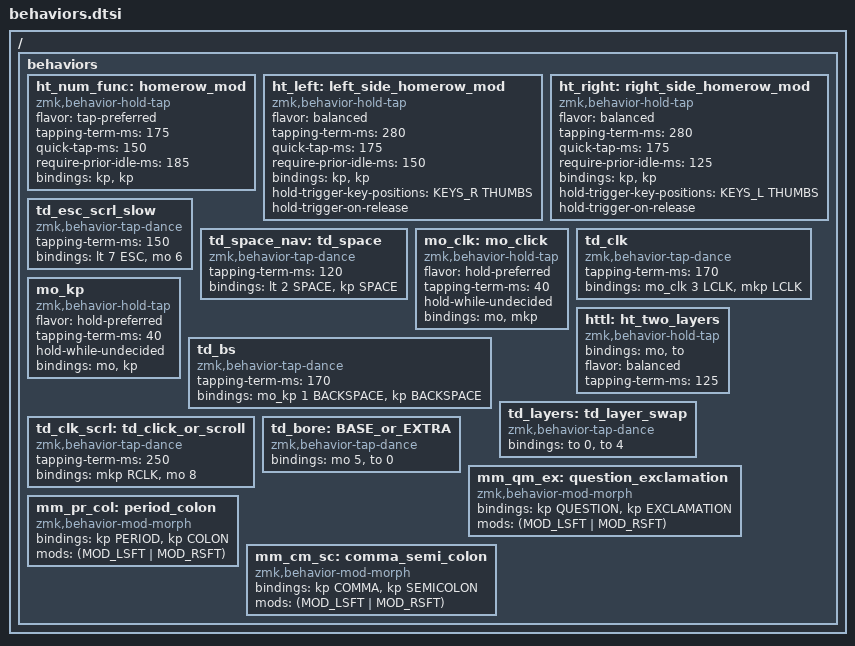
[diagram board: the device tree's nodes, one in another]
#define KEYS_L 0 1 2 3 4 5 12 13 14 15 16 17 24 25 26 27 28 29 36 37 38 19 20 21 22  // 定义左手按键矩阵位置的索引集合
#define KEYS_R 6 7 8 9 10 11 18 19 20 21 22 23 30 31 32 33 34 35 39 40 16 15 14 13  // 定义右手按键矩阵位置的索引集合
#define THUMBS 36 37 38 39 40  // 定义大拇指区按键矩阵位置的索引集合

/ {
    behaviors {
        ht_num_func: homerow_mod {
            compatible = "zmk,behavior-hold-tap";  // 定义一个 hold-tap 行为（按一下触发 tap，长按触发 hold）
            #binding-cells = <2>;                  // 该行为需要两个绑定：一个是 hold，一个是 tap
            flavor = "tap-preferred";              // 优先触发 tap 行为
            tapping-term-ms = <175>; // 按键按下超过 175ms 视为 hold，否则是 tap
            quick-tap-ms = <150>; // 如果在 150ms 内再次按下，则强制视为 tap
            require-prior-idle-ms = <185>; // 如果前一个按键在 185ms 内触发，则不触发 hold
            bindings = <&kp>, <&kp>;  // 第一个是 hold 的行为（kp=按键），第二个是 tap 的行为
        };

        // 左手主行修饰键（HRM）
        ht_left: left_side_homerow_mod {
            compatible = "zmk,behavior-hold-tap";
            #binding-cells = <2>;
            flavor = "balanced";                  // 平衡模式：tap 和 hold 取舍更均衡
            tapping-term-ms = <280>;              // 280ms 内算 tap
            quick-tap-ms = <175>;                 // 快速双击 175ms 内算 tap
            require-prior-idle-ms = <150>;
            bindings = <&kp>, <&kp>;
            hold-trigger-key-positions = <KEYS_R THUMBS>; // 当右手或拇指键被按下时，更容易触发 hold
            hold-trigger-on-release;              // 松开键时才决定是 hold
        };

        // 右手主行修饰键（HRM）
        ht_right: right_side_homerow_mod {
            compatible = "zmk,behavior-hold-tap";
            #binding-cells = <2>;
            flavor = "balanced";
            tapping-term-ms = <280>;
            quick-tap-ms = <175>;
            require-prior-idle-ms = <125>;
            bindings = <&kp>, <&kp>;
            hold-trigger-key-positions = <KEYS_L THUMBS>; // 当左手或拇指键被按下时，更容易触发 hold
            hold-trigger-on-release;
        };

        // Tap Dance：ESC 和 Scroll（慢）
        td_esc_scrl_slow: td_esc_scrl_slow {
            compatible = "zmk,behavior-tap-dance"; // 定义一个 tap-dance 行为：同一个按键不同点按次数触发不同功能
            #binding-cells = <0>;
            tapping-term-ms = <150>; // 在 150ms 内的按键动作会被合并
            bindings = <&lt 7 ESC>, <&mo 6>; // 单击=ESC，长按=切换到 layer 7，双击=切换到 layer 6
        };

        // Tap Dance：空格键 + 导航层
        td_space_nav: td_space {
            compatible = "zmk,behavior-tap-dance";
            #binding-cells = <0>;
            tapping-term-ms = <120>;
            bindings = <&lt 2 SPACE>, <&kp SPACE>; // 单击=空格，长按=进入 layer 2，双击=空格
        };

        // Hold-Tap：点击/点击时触发鼠标点击
        mo_clk: mo_click {
            compatible = "zmk,behavior-hold-tap";
            #binding-cells = <2>;
            flavor = "hold-preferred"; // 优先触发 hold 行为
            tapping-term-ms = <40>;    // 很短的判断时间
            hold-while-undecided;      // 未决时保持 hold
            bindings = <&mo>, <&mkp>;  // hold=切换层，tap=鼠标点击
        };

        // Tap Dance：点击或点击/双击触发不同鼠标功能
        td_clk: td_clk {
            compatible = "zmk,behavior-tap-dance";
            #binding-cells = <0>;
            tapping-term-ms = <170>;
            bindings = <&mo_clk 3 LCLK>, <&mkp LCLK>; // 单击=鼠标左键，长按=进入 layer 3，双击=鼠标左键
        };

        // Hold-Tap：键盘模式
        mo_kp: mo_kp {
            compatible = "zmk,behavior-hold-tap";
            #binding-cells = <2>;
            flavor = "hold-preferred";
            tapping-term-ms = <40>;
            hold-while-undecided;
            bindings = <&mo>, <&kp>; // hold=切换层，tap=普通按键
        };

        // Tap Dance：退格键
        td_bs: td_bs {
            compatible = "zmk,behavior-tap-dance";
            #binding-cells = <0>;
            tapping-term-ms = <170>;
            bindings = <&mo_kp 1 BACKSPACE>, <&kp BACKSPACE>; // 单击=退格，长按=进入 layer 1，双击=退格
        };

        // Hold-Tap：在两个层之间切换
        httl: ht_two_layers {
            compatible = "zmk,behavior-hold-tap";
            bindings = <&mo>, <&to>; // hold=切换层，tap=跳转层
            #binding-cells = <2>;
            flavor = "balanced";
            tapping-term-ms = <125>;
        };

        // Tap Dance：层切换
        td_layers: td_layer_swap {
            compatible = "zmk,behavior-tap-dance";
            #binding-cells = <0>;
            bindings = <&to 0>, <&to 4>; // 单击=跳转到 layer 0，双击=跳转到 layer 4
        };

        // Tap Dance：点击或滚动
        td_clk_scrl: td_click_or_scroll {
            compatible = "zmk,behavior-tap-dance";
            #binding-cells = <0>;
            tapping-term-ms = <250>;
            bindings = <&mkp RCLK>, <&mo 8>;  // 单击=鼠标右键，长按=进入 layer 8，双击=鼠标右键
        };

        // Tap Dance：基础层或额外层
        td_bore: BASE_or_EXTRA {
            compatible = "zmk,behavior-tap-dance";
            #binding-cells = <0>;
            bindings = <&mo 5>, <&to 0>; // 单击=进入 layer 5，双击=跳转到 layer 0
        };

        // Mod Morph：问号和感叹号
        mm_qm_ex: question_exclamation {
            compatible    = "zmk,behavior-mod-morph"; // 根据修饰键变化
            #binding-cells = <0>;
            bindings      = <&kp QUESTION>, <&kp EXCLAMATION>; // 默认=问号，Shift=感叹号
            mods          = <(MOD_LSFT | MOD_RSFT)>; // 当左或右 Shift 按下时触发感叹号
        };

        // Mod Morph：句号和冒号
        mm_pr_col: period_colon {
            compatible    = "zmk,behavior-mod-morph";
            #binding-cells = <0>;
            bindings      = <&kp PERIOD>, <&kp COLON>; // 默认=句号，Shift=冒号
            mods          = <(MOD_LSFT | MOD_RSFT)>;
        };

        // Mod Morph：逗号和分号
        mm_cm_sc: comma_semi_colon {
            compatible    = "zmk,behavior-mod-morph";
            #binding-cells = <0>;
            bindings      = <&kp COMMA>, <&kp SEMICOLON>; // 默认=逗号，Shift=分号
            mods          = <(MOD_LSFT | MOD_RSFT)>;
        };
    };
};
